# I2S1_1.0 register map
Vendor: Texas Instruments
Peripheral module from a debugger description file (folder mspm33c321x).
Registers are 32-bit, read-write, no defined reset value unless marked. A register's access mark holds for its fields unless they carry their own. Offsets are as the file gives them; lines under a group give offsets from that group; [hi:lo] are bit positions; {n}, {i} and the like mark numbered series; 'fields as' and 'values as' point back to an identical list; <NAME> marks a mode.

## I2S1
0x800 I2S1_GPRCM group
  0x00 I2S1_PWREN — Power enable
    [0] ENABLE — Enable the power
      0=DISABLE (Disable Power); 1=ENABLE (Enable Power)
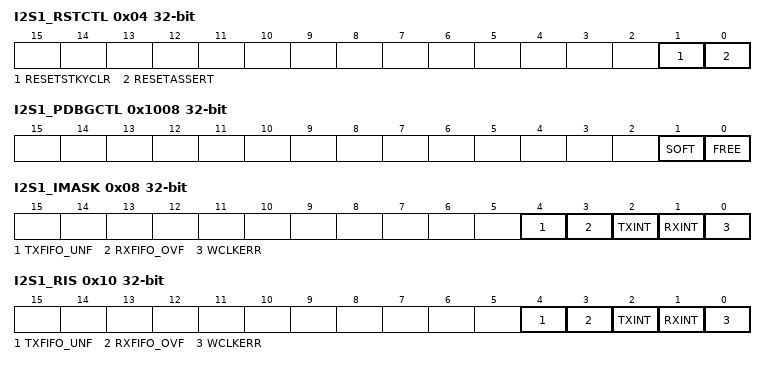
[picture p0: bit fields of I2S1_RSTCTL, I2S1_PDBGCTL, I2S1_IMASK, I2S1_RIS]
  0x04 I2S1_RSTCTL — Reset Control
    [1] RESETSTKYCLR — Clear the RESETSTKY bit in the STAT register
      0=NOP (Writing 0 has no effect); 1=CLR (Clear reset sticky bit)
    [0] RESETASSERT — Assert reset to the peripheral
      0=NOP (Writing 0 has no effect); 1=ASSERT (Assert reset)
  0x08 I2S1_CLKCFG — Peripheral Clock Configuration Register
    [8] BLOCKASYNC — Async Clock Request is blocked from starting SYSOSC or forcing bus clock to 32MHz
      0=DISABLE (Not block async clock request); 1=ENABLE (Block async clock request)
  0x14 I2S1_GPRCM_STAT ro — Status Register
    [16] RESETSTKY — This bit indicates, if the peripheral was reset, since this bit was cleared by RESETSTKYCLR in the RSTCTL register
      0=NORES (The peripheral has not been reset since this bit was last cleared by RESETSTKYCLR in the RSTCTL register); 1=RESET (The peripheral was reset since the last bit clear)
0x1008 I2S1_PDBGCTL — Peripheral Debug Control
  [1] SOFT — Soft halt boundary control. This function is only available, if [FREE] is set to 'STOP'
    0=IMMEDIATE (The peripheral will halt immediately, even if the resultant state will result in corruption if the system is restarted); 1=DELAYED (The peripheral blocks the debug freeze until it has reached a boundary where it can resume without corruption)
  [0] FREE — Free run control
    0=STOP (The peripheral freezes functionality while the Core Halted input is asserted and resumes when it is deasserted.); 1=RUN (The peripheral ignores the state of the Core Halted input)
0x1020 I2S1_CPU_INT group
  0x00 I2S1_IIDX ro — Interrupt index
    [7:0] STAT — Module Interrupt Vector Value. This register provides the highes priority interrupt index. A read clears the corresponding interrupt flag in RIS and MIS registers. 15h-1Fh = Reserved
      0=NO_INTR (No interrupt pending); 1=WCLKERR (WCLK Error); 2=RXIFG (Receive interrupt; Interrupt Flag: RX); 3=TXIFG (Transmit interrupt; Interrupt Flag: TX); 4=RXFIFO_OFV_EVT (RX FIFO Overflow Event/interrupt pending); 5=TXFIFO_UNF_EVT (TX FIFO underflow interrupt); 16=DMA_DONE_RX (DMA DONE on RX); 17=DMA_DONE_TX (DMA DONE on TX); 19=DMA_PREIRQ_RX (DMA PRE IRQ INTERRUPT); 20=DMA_PREIRQ_TX (DMA PRE IRQ INTERRUPT)
  0x08 I2S1_IMASK — Interrupt Mask Register Selects mask states of the flags in [IRQFLAGS.*] that contribute to the **I2S_IRQ** event.
    [4] TXFIFO_UNF — TX FIFO underflow interrupt mask
      0=CLR (Clear Interrupt Mask); 1=SET (Set Interrupt Mask)
    [3] RXFIFO_OVF — RXFIFO overflow event mask.
      0=CLR (Clear Interrupt Mask); 1=SET (Set Interrupt Mask)
    [2] TXINT — Enable Transmit Interrupt.
      0=CLR (Clear Interrupt Mask); 1=SET (Set Interrupt Mask)
    [1] RXINT — Enable Receive Interrupt.
      0=CLR (Clear Interrupt Mask); 1=SET (Set Interrupt Mask)
    [0] WCLKERR — WCLKERR interrupt mask
      0=DIS (Disable the interrupt mask); 1=EN (Enable the interrupt mask)
  0x10 I2S1_RIS access per field — This registers gives the raw interrupt status
    [4] TXFIFO_UNF rw — TX FIFO Underflow Interrupt
      0=CLR (Interrupt did not occur); 1=SET (Interrupt occurred)
    [3] RXFIFO_OVF rw — RXFIFO overflow event. This interrupt is set if an RX FIFO overflow has been detected.
      0=CLR (Interrupt did not occur); 1=SET (Interrupt occurred)
    [2] TXINT rw — Transmit Interrupt.
      0=CLR (Interrupt did not occur); 1=SET (Interrupt occured)
    [1] RXINT rw — Receive Interrupt.
      0=CLR (Interrupt did not occur); 1=SET (Interrupt occured)
    [0] WCLKERR ro — This interrupt is set when: - An unexpected **WCLK** edge occurs during the data delay period of a phase. Note unexpected **WCLK** edges during the word and idle periods of the phase are not detected. - In dual-phase mode, when two **WCLK** edges are less than 4 **BCLK** cycles apart. - In single-phase mode, when a **WCLK** pulse occurs before the last channel. This error requires a complete restart since word synchronization has been lost.
      0=CLR (Interrupt did not occur); 1=SET (Interrupt occured)
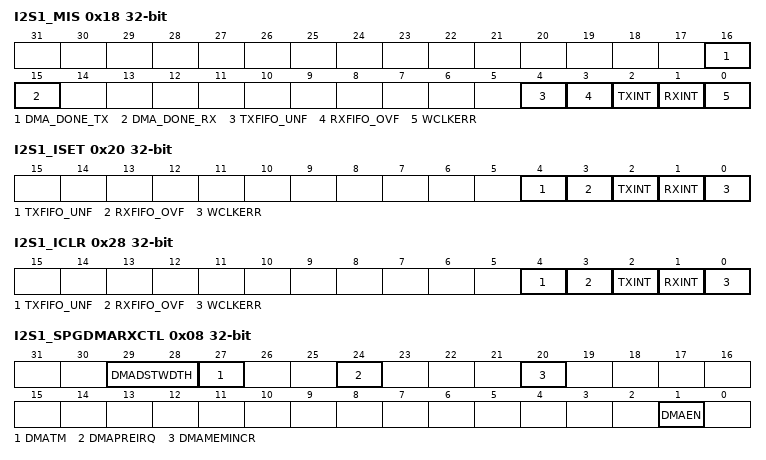
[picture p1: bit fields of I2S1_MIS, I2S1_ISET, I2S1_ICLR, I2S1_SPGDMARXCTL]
  0x18 I2S1_MIS access per field — This registers gives the raw interrupt status
    [16] DMA_DONE_TX rw — Masked DMA Done on TX Event Channel Interrupt
      0=CLR (Interrupt did not occur); 1=SET (Interrupt occured)
    [15] DMA_DONE_RX rw — Masked DMA Done on RX Event Channel Interrupt
      0=CLR (Interrupt did not occur); 1=SET (Interrupt occured)
    [4] TXFIFO_UNF rw — TX FIFO underflow interrupt
      0=CLR (Interrupt did not occur); 1=SET (Interrupt occurred)
    [3] RXFIFO_OVF rw — Masked RXFIFO overflow event. This interrupt is set if an RX FIFO overflow has been detected.
      0=CLR (Interrupt did not occur); 1=SET (Interrupt occurred)
    [2] TXINT rw — Masked Transmit Interrupt.
      0=CLR (Interrupt did not occur); 1=SET (Interrupt occured)
    [1] RXINT rw — Masked Receive Interrupt.
      0=CLR (Interrupt did not occur); 1=SET (Interrupt occured)
    [0] WCLKERR ro — This interrupt is set when: - An unexpected **WCLK** edge occurs during the data delay period of a phase. Note unexpected **WCLK** edges during the word and idle periods of the phase are not detected. - In dual-phase mode, when two **WCLK** edges are less than 4 **BCLK** cycles apart. - In single-phase mode, when a **WCLK** pulse occurs before the last channel. This error requires a complete restart since word synchronization has been lost.
      0=CLR (Interrupt did not occur); 1=SET (Interrupt occured)
  0x20 I2S1_ISET — Interrupt Set Register. This register can be used by software for diagnostics and safety checking purposes.
    [4] TXFIFO_UNF — Set TX FIFO Underflow Event
      0=NO_EFFECT (Writing has no effect); 1=SET (Set interrupt)
    [3] RXFIFO_OVF — Set RXFIFO overflow event.
      0=NO_EFFECT (Writing 0 has no effect); 1=SET (Set Interrupt)
    [2] TXINT — Set Transmit Interrupt.
      0=NO_EFFECT (Writing 0 has no effect); 1=SET (Set Interrupt)
    [1] RXINT — Set Receive Interrupt.
      0=NO_EFFECT (Writing 0 has no effect); 1=SET (Set Interrupt)
    [0] WCLKERR — This field sets the interrupt WCLKERR
      0=NOEFF (Writing 0 has no effect); 1=SET (Set interrupt)
  0x28 I2S1_ICLR — Interrupt clear register. This register allows software to clear interrupts.
    [4] TXFIFO_UNF — Clear TXFIFO underflow event
      0=NO_EFFECT (Writing has no effect); 1=CLR (Clear interrupt)
    [3] RXFIFO_OVF — Clear RXFIFO overflow event.
      0=NO_EFFECT (Writing 0 has no effect); 1=CLR (Clear Interrupt)
    [2] TXINT — Clear Transmit Interrupt.
      values as RXFIFO_OVF
    [1] RXINT — Clear Receive Interrupt.
      values as RXFIFO_OVF
    [0] WCLKERR — This field clears the interrupt WCLKERR
      0=NOEFF (Writing 0 has no effect); 1=CLR (Clear interrupt)
0x10B0 I2S1_SPGDMA group
  0x00 I2S1_SPGDMARXSZ — DMA Channel Size
    [15:0] SIZE — DMA Channel Size in number of transfers
      0=MINIMUM (Smallest value); 0xFFFF=MAXIMUM (Highest possible value)
  0x04 I2S1_SPGDMARXDA — DMA Channel Destination Address
    [31:0] ADDR
      0=MINIMUM (Smallest value); 0xFFFFFFFF=MAXIMUM (Highest possible value)
  0x08 I2S1_SPGDMARXCTL — DMA Channel Control
    [29:28] DMADSTWDTH — DMA destination width. This bit selects the destination as a byte, half word, word or long word.
      0=BYTE (Destination data width is BYTE (8-bit)); 1=HALF (Destination data width is HALF-WORD (16-bit)); 2=WORD (Destination data width is WORD (32-bit))
    [27] DMATM — DMA transfer mode register
      0=SINGLE (Single transfer. Each transfers requires a new trigger. When the DMASZ counts down to zero an event can be generated and the DMAEN is cleared.); 1=RPTSNGL (Repeated single transfer. Each transfers requires a new trigger. When the DMASZ counts down to zero an event can be generated. After the last transfer the DMASA, DMADA, DAMSZ registers are restored to its initial value and the DMAEN stays enabled.)
    [24] DMAPREIRQ — Enable an early IRQ event. This can help software to react quicker to and DMA done event or allows some additional configuration before the channel is complete. Note: This register is only available in a FULL-channel configuration. Please consult the datasheet of the specific device to map which channel number has FULL or BASIC capability. In a BASIC configuration this register is a read only value and always reads as 0x0.
      0=PREIRQ_DISABLE (Pre-IRQ event disabled.); 1=PREIRQ_HALF (Issure Pre-IRQ event when DMASZ reached the half size point of the original transfer size)
    [20] DMAMEMINCR — DMA destination increment. This bit selects automatic incrementing or decrementing of the destination address DMADA for each transfer. The amount of change to the DMADA is based on the definitin in the DMADSTWDTH. For example an increment of 1 (+1) on a WORD transfer will increment the DMADA by 4.
      0=INCREMENT (Incremented by 1 (+1 * DMADSTWDTH)); 1=DECREMENT (Decremented by 1 (-1 * DMADSTWDTH))
    [1] DMAEN — DMA enable
      0=DISABLE (DMA channel disabled); 1=ENABLE (DMA channel enabled)
  0x10 I2S1_SPGDMATXSZ — DMA Channel Size
    fields as I2S1_SPGDMA.I2S1_SPGDMARXSZ
  0x14 I2S1_SPGDMATXSA — DMA Channel Destination Address
    fields as I2S1_SPGDMA.I2S1_SPGDMARXDA
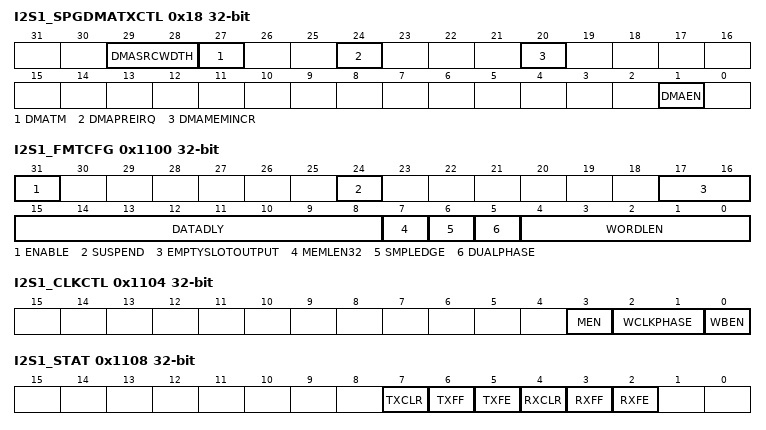
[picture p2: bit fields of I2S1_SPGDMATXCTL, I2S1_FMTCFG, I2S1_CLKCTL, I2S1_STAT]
  0x18 I2S1_SPGDMATXCTL — DMA Channel Control
    [29:28] DMASRCWDTH — DMA source width. This bit selects the source data width as a byte, half word, word or long word.
      0=BYTE (Source data width is BYTE (8-bit)); 1=HALF (Source data width is HALF-WORD (16-bit)); 2=WORD (Source data width is WORD (32-bit))
    [27] DMATM — DMA transfer mode register Note: The repeat-single (2h) and repeat-block (3h) transfer are only available in a FULL-channel configuration. Please consult the datasheet of the specific device to map which channel number has FULL or BASIC capability. In a BASIC channel configuration only the values for single (0h) and block (1h) transfer can be set.
      values as I2S1_SPGDMA.I2S1_SPGDMARXCTL.DMATM
    [24] DMAPREIRQ — Enable an early IRQ event. This can help software to react quicker to and DMA done event or allows some additional configuration before the channel is complete. Note: This register is only available in a FULL-channel configuration. Please consult the datasheet of the specific device to map which channel number has FULL or BASIC capability. In a BASIC configuration this register is a read only value and always reads as 0x0.
      values as I2S1_SPGDMA.I2S1_SPGDMARXCTL.DMAPREIRQ
    [20] DMAMEMINCR — DMA destination increment. This bit selects automatic incrementing or decrementing of the destination address DMADA for each transfer. The amount of change to the DMADA is based on the definitin in the DMADSTWDTH. For example an increment of 1 (+1) on a WORD transfer will increment the DMADA by 4.
      0=INCREMENT (Incremented by 1 (+1 * DMASRCWDTH)); 1=DECREMENT (Decremented by 1 (-1 * DMASRCWDTH))
    [1] DMAEN — DMA enable
      values as I2S1_SPGDMA.I2S1_SPGDMARXCTL.DMAEN
0x10E4 I2S1_INTCTL — Interrupt control register
  [0] INTEVAL — Writing a 1 to this field re-evaluates the interrupt sources.
    0=DISABLE (The interrupt or event line is disabled.); 1=EVAL (The interrupt or event line is in software mode. Software must clear the RIS.)
0x1100 I2S1_FMTCFG — This register configures the serial interface format
  [31] ENABLE — I2S Module Enable. If the I2S is disabled in the middle of transmission or reception, it completes the current character before stopping. If ENABLE bit is not set, all registers can still be accessed and updated. It is recommended to setup and change I2S operation mode whhile ENABLE bit is cleared to avoid unpredictable behavior during setup or update. If disabled, I2S module will not send or receive any data.
    0=DISABLE (Disable Module); 1=ENABLE (Enable module)
  [24] SUSPEND — Suspend external communication
    0=DISABLE (Functional mode resumed); 1=ENABLE (External communication suspended)
  [17:16] EMPTYSLOTOUTPUT — The field configures the **EMPTYSLOTOUTPUT** data pin direction
    0=zero (Send out zeroes in empty slots); 1=one (send out ones in empty slot); 2=Tristate line during empty slot
  [15:8] DATADLY — This field configures the number of **BCLK** periods between a **WCLK** edge and **MSB** of the first word in a phase Note: When 0, **MSB** of the next word will be output in the idle period between **LSB** of the previous word and the start of the next word. Otherwise logical 0 will be output until the data delay has expired.
    0=ZERO (Zero **BCLK** periods - **LJF** and **DSP** formats); 1=ONE (One **BCLK** periods - **I2S** and **DSP** formats); 2=TWO (Two(Min) **BCLK** periods - **RJF** format); 255=MAX (Max(255) **BCLK** periods - **RJF** format)
  [7] MEMLEN32 — This register configures the size of each word stored to or loaded from memory
    0=16BIT (16-bit (one 16 bit access per sample)); 1=32BIT (32-bit(one 32-bit access per sample))
  [6] SMPLEDGE — This field configures the sample edge/ transfer edge of data (and **WCLK**) on **BCLK**
    0=NEGEDGE (Data is sampled on the negative edge and clocked out on the positive edge.); 1=POSEDGE (Data is sampled on the positive edge and clocked out on the negative edge.)
  [5] DUALPHASE — This field selects between dual-phase or single-phase format
    0=SINGLEPHASE (Single-phase: **DSP** format); 1=DUALPHASE (Dual-phase: **I2S**, **LJF** and **RJF** formats)
  [4:0] WORDLEN — Number of bits per word (8-32): In single-phase format, this is the exact number of bits per word. In dual-phase format, this is the maximum number of bits per word. Values below 8 and above 32 give undefined behavior. Data written to memory is always aligned to 16 or 32 bits as defined by [MEMLEN32]. Bit widths that differ from this alignment will either be truncated or zero padded.
0x1104 I2S1_CLKCTL — This register controls internal audio clock
  [3] MEN — This field configures the **MCLK** generation
    0=DIS (Disable the generation); 1=EN (Enable the generation)
  [2:1] WCLKPHASE — The field configures how the WCLK division ratio is calculated and used to generate different duty cycles (See [WCLKDIV.WDIV])
  [0] WBEN — This field configures **WCLK**/**BCLK** generation
    0=DIS (Disables the generation); 1=EN (Enable the generation)
0x1108 I2S1_STAT ro — UART Status Register
  [7] TXCLR — TX FIFO Clear Status
    0=CLEARED (FIFO is not cleared); 1=SET (FIFO clear is complete)
  [6] TXFF — UART Transmit FIFO Full The meaning of this bit depends on the state of the FEN bit in the CTL0 register.
    0=CLEARED (The transmitter is not full.); 1=SET (If the FIFO is disabled (FEN is 0), the transmit holding register is full. If the FIFO is enabled (FEN is 1), the transmit FIFO is full.)
  [5] TXFE — UART Transmit FIFO Empty The meaning of this bit depends on the state of the FEN bit in the CTL0 register.
    0=CLEARED (The transmitter has data to transmit.); 1=SET (If the FIFO is disabled (FEN is 0), the transmit holding register is empty. If the FIFO is enabled (FEN is 1), the transmit FIFO is empty.)
  [4] RXCLR — RX FIFO Clear Status
    values as TXCLR
  [3] RXFF — UART Receive FIFO Full The meaning of this bit depends on the state of the FEN bit in the CTL0 register.
    0=CLEARED (The receiver can receive data.); 1=SET (If the FIFO is disabled (FEN is 0), the receive holding register is full. If the FIFO is enabled (FEN is 1), the receive FIFO is full.)
  [2] RXFE — UART Receive FIFO Empty The meaning of this bit depends on the state of the FEN bit in the CTL0 register.
    0=CLEARED (The receiver is not empty.); 1=SET (If the FIFO is disabled (FEN is 0), the receive holding register is empty. If the FIFO is enabled (FEN is 1), the receive FIFO is empty.)
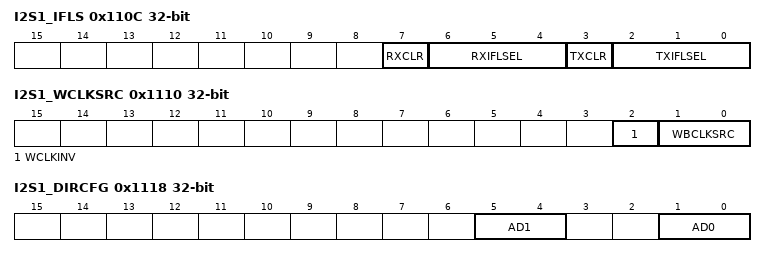
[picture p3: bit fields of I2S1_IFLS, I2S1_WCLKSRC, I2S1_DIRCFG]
0x110C I2S1_IFLS — UART Interrupt FIFO Level Select Register
  [7] RXCLR — RX FIFO CLEAR. Setting this bit will clear the RX FIFO contents.
    0=DISABLE (Disable FIFO clear); 1=ENABLE (Enable FIFO Clear)
  [6:4] RXIFLSEL — UART Receive Interrupt FIFO Level Select The trigger points for the receive interrupt are as follows: Note: In ULP domain the trigger levels are used for: 0: LVL_1_4 4: LVL_FULL For undefined settings the default configuration is used.
    1=LVL_1_4 (RX FIFO >= 1/4 full); 2=LVL_1_2 (RX FIFO >= 1/2 full (default)); 3=LVL_3_4 (RX FIFO >= 3/4 full); 5=LVL_FULL (RX FIFO is full); 6=LVL_ALMOST_FULL (RX_FIFO >= (MAX_FIFO_LEN -1)); 7=LVL_ALMOST_EMPTY (RX_FIFO <= 1)
  [3] TXCLR — TX FIFO CLEAR. Setting this bit will clear the TX FIFO contents.
    0=DISABLE (Disable FIFO clear); 1=ENABLE (Enable FIFO Clear)
  [2:0] TXIFLSEL — FIFO Level Select for generating events (interrupt/dma). Note: for undefined settings the default configuration is used.
    1=LVL_3_4 (TX FIFO <= 3/4 empty); 2=LVL_1_2 (TX FIFO <= 1/2 empty (default)); 3=LVL_1_4 (TX FIFO <= 1/4 empty); 5=LVL_EMPTY (TX FIFO is empty); 6=LVL_ALMOST_EMPTY (TX FIFO <= 1); 7=LVL_ALMOST_FULL (TX_FIFO >= (MAX_FIFO_LEN -1))
0x1110 I2S1_WCLKSRC — This register configures the **WCLK** Source
  [2] WCLKINV — This field Inverts **WCLK** source (pad or internal).
    0=NOT_INTVERTED (Source is not intverted); 1=INVERTED (Source is inverted)
  [1:0] WBCLKSRC — This field selects **WCLK**/**BCLK** source for **I2S**.
    0=NONE (None ('0')); 1=EXT (External **WCLK** generator, from pad); 2=INT (Internal **WCLK** generator, from module PRCM); 3=RESERVED (Not supported. Will give same **WCLK** as 'NONE' ('00'))
0x1118 I2S1_DIRCFG — This register configures the direction of data pins(**AD0**/**AD1**)
  [5:4] AD1 — The field configures the **AD1** data pin direction
    0=DIS (Not in use (disabled)); 1=IN (Input); 2=OUT (Output)
  [1:0] AD0 — The field configures the **AD0** data pin direction
    0=DIS (Not in use (disabled)); 1=IN (Input); 2=OUT (Output)
0x1120 I2S1_TXDATA — UART Transmit Data Register
  [31:0] DATA — Data Transmitted or Received Data that is to be transmitted via the UART is written to this field. When read, this field contains the data that was received by the UART.
    values as I2S1_SPGDMA.I2S1_SPGDMARXDA.ADDR
0x1124 I2S1_RXDATA ro — UART Receive Data Register
  [31:0] DATA — Received Data. When read, this field contains the data that was received by the UART.
    values as I2S1_SPGDMA.I2S1_SPGDMARXDA.ADDR
0x1148 I2S1_WMASK0 — This register configures the word selection dit mask for data pin 0(**AD0**)
  [15:0] MASK — Bit-mask indicating valid channels in a frame on AD0. In single-phase mode, each bit represents one channel, starting with **LSB** for the first word in the frame. A frame can contain up to 8/16 channels based on SoC configuration. Channels that are not included in the mask will not be sampled nor stored in memory; data clocked out in these slots is as per configured EMPTYSLOTOUTPUT. In dual-phase mode, only the two **LSB**s are considered. For a stereo configuration, set both bits. For a mono configuration, set bit 0 only. In mono mode, only channel 0 will be sampled and stored to memory, and channel 0 will be repeated when clocked out. In mono mode, only channel 0 will be sampled and stored to memory, and channel 0 will be repeated in the second phase when clocked out. If all bits are zero, no input words will be stored to memory, and the output data lines will be constant '0'. This can be utilized when **PWM** debug output is desired without any actively used output pins.
0x114C I2S1_WMASK1 — This register configures the word selection dit mask for data pin 1(**AD1**)
  [15:0] MASK — Bit-mask indicating valid channels in a frame on AD1. In single-phase mode, each bit represents one channel, starting with **LSB** for the first word in the frame. A frame can contain up to 8/16 channels based on SoC configuration. Channels that are not included in the mask will not be sampled nor stored in memory; data clocked out in these slots is as per configured EMPTYSLOTOUTPUT. In dual-phase mode, only the two **LSB**s are considered. For a stereo configuration, set both bits. For a mono configuration, set bit 0 only. In mono mode, only channel 0 will be sampled and stored to memory, and channel 0 will be repeated when clocked out. In mono mode, only channel 0 will be sampled and stored to memory, and channel 0 will be repeated in the second phase when clocked out. If all bits are zero, no input words will be stored to memory, and the output data lines will be constant '0'. This can be utilized when **PWM** debug output is desired without any actively used output pins.
0x1160 I2S1_MCLKDIV — This field configures **MCLK** division ratio
  [9:0] MDIV — An unsigned factor of the division ratio used to generate **MCLK** [2-1024]: **MCLK** = MCUCLK/MDIV[Hz] **MCUCLK** is upto 96MHz. A value of 0 is interpreted as 1024. A value of 1 is invalid. If MDIV is odd the low phase of the clock is one **MCUCLK** period longer than the high phase.
0x1164 I2S1_WCLKDIV — Configures WCLK division ratio
  [15:0] WDIV — If[CLKCTL.WCLKPHASE]= 0, Single phase. **WCLK**is high one**BCLK**period and low WDIV[9:0] (unsigned, [1-1023])**BCLK**periods. **WCLK**=**MCUCLK**/ BDIV*(WDIV[9:0] + 1) [Hz] **MCUCLK**upto 96MHz. If[CLKCTL.WCLKPHASE.*]= 1, Dual phase. Each phase on**WCLK**(50% duty cycle) is WDIV[9:0] (unsigned, [1-1023])**BCLK**periods. **WCLK**=**MCUCLK**/ BDIV*(2*WDIV[9:0]) [Hz] If[CLKCTL.WCLKPHASE.*] = 2, User defined. **WCLK**is high WDIV[7:0] (unsigned, [1-255])**BCLK**periods and low WDIV[15:8] (unsigned, [1-255])**BCLK**periods. **WCLK**=**MCUCLK**/ (BDIV*(WDIV[7:0] + WDIV[15:8]) [Hz]
0x1168 I2S1_BCLKDIV — This field configures **BCLK** division ratio
  [9:0] BDIV — An unsigned factor of the division ratio used to generate **BCLK** [2-1024]: **BCLK** = MCUCLK/BDIV[Hz] A value of 0 is interpreted as 1024. A value of 1 is invalid. If BDIV is odd and [FMTCFG.SMPLEDGE] = 0, the low phase of the clock is one **MCUCLK** period longer than the high phase. If BDIV is odd and [FMTCFG.SMPLEDGE] = 1 , the high phase of the clock is one **MCUCLK** period longer than the low phase.
